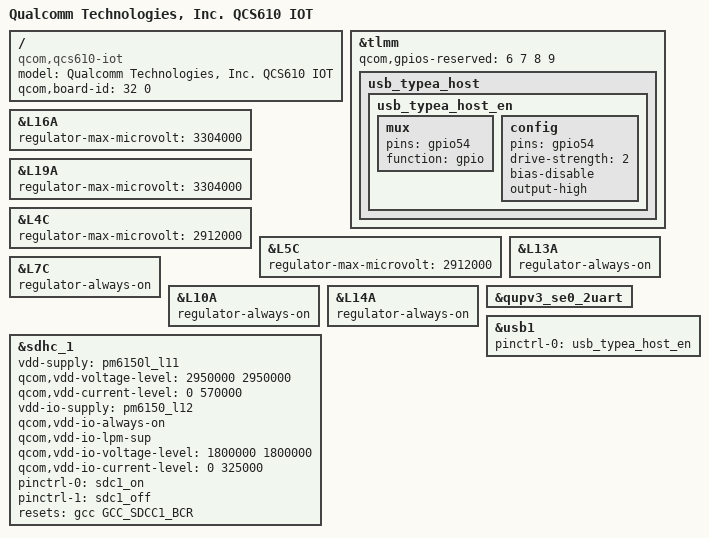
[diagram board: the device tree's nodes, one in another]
// SPDX-License-Identifier: BSD-3-Clause
/*
 * Copyright (c) 2025 Qualcomm Innovation Center, Inc. All rights reserved.
 */

#include <dt-bindings/gpio/gpio.h>
#include <dt-bindings/iio/qcom,spmi-vadc.h>
#include <dt-bindings/input/input.h>
#include <dt-bindings/clock/qcom,gcc-sm6150.h>

/ {
	model = "Qualcomm Technologies, Inc. QCS610 IOT";
	compatible = "qcom,qcs610-iot", "qcom,qcs610", "qcom,iot";
	qcom,board-id = <32 0>;
};

&tlmm {
	qcom,gpios-reserved = <6 7 8 9>;
};

&L16A {
	regulator-max-microvolt = <3304000>;
};

&L19A {
	regulator-max-microvolt = <3304000>;
};

&L4C {
	regulator-max-microvolt = <2912000>;
};

&L5C {
	regulator-max-microvolt = <2912000>;
};

&L13A {
	regulator-always-on;
};

&L7C {
	regulator-always-on;
};

&L10A {
	regulator-always-on;
};

&L14A {
	regulator-always-on;
};

&qupv3_se0_2uart {
	status = "ok";
};

&tlmm {
	usb_typea_host {
		usb_typea_host_en: usb_typea_host_en {
			mux {
				pins = "gpio54";
				function = "gpio";
			};

			config {
				pins = "gpio54";
				drive-strength = <2>;
				bias-disable;
				output-high;
			};
		};
	};
};

&usb1 {
	pinctrl-names = "default";
	pinctrl-0 = <&usb_typea_host_en>;
	status = "okay";
};

&sdhc_1 {
	vdd-supply = <&pm6150l_l11>;
	qcom,vdd-voltage-level = <2950000 2950000>;
	qcom,vdd-current-level = <0 570000>;

	vdd-io-supply = <&pm6150_l12>;
	qcom,vdd-io-always-on;
	qcom,vdd-io-lpm-sup;
	qcom,vdd-io-voltage-level = <1800000 1800000>;
	qcom,vdd-io-current-level = <0 325000>;

	pinctrl-names = "default", "sleep";
	pinctrl-0 = <&sdc1_on>;
	pinctrl-1 = <&sdc1_off>;

	resets = <&gcc GCC_SDCC1_BCR>;
	reset-names = "core_reset";

	status = "ok";
};
